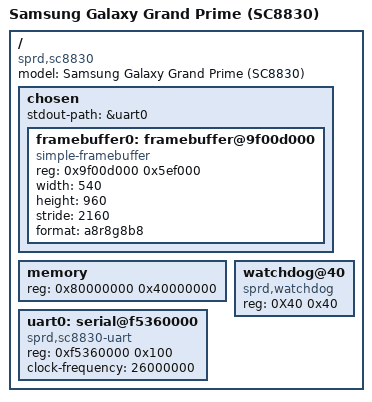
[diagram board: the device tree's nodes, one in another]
/dts-v1/;

/ {
	model = "Samsung Galaxy Grand Prime (SC8830)";
	compatible = "sprd,sc8830";
	#address-cells = <1>;
	#size-cells = <1>;

	chosen {
		#address-cells = <1>;
		#size-cells = <1>;
		stdout-path = &uart0;

		framebuffer0: framebuffer@9f00d000 {
			compatible = "simple-framebuffer";
			reg = <0x9f00d000 0x5ef000>;
			width = <540>;
			height = <960>;
			stride = <2160>;
			format = "a8r8g8b8";
		};
	};

	memory {
		device_type = "memory";
		reg = <0x80000000 0x40000000>;
	};

	uart0: serial@f5360000 {
		compatible = "sprd,sc8830-uart";
		reg = <0xf5360000 0x100>;
		clock-frequency = <26000000>;
		status = "okay";
	};
	watchdog@40 {
		compatible = "sprd,watchdog";
		reg = <0X40 0x40>;
	};
};
